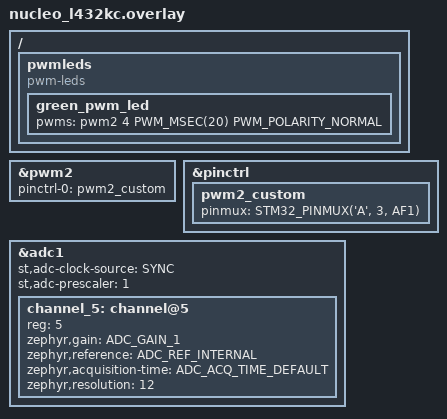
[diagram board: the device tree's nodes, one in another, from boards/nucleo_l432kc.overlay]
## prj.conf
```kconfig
CONFIG_PWM=y
CONFIG_ADC=y
CONFIG_GPIO=y
```

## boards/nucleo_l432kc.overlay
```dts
/{
    pwmleds: pwmleds {
        compatible = "pwm-leds";
        status = "okay";
        green_pwm_led: green_pwm_led {
            pwms = <&pwm2 4 PWM_MSEC(20) PWM_POLARITY_NORMAL>; // &pwm2 links to TIM2_CH4 and PA3
        };
    };
};

&pwm2 {
    status = "okay";
    pinctrl-0 = <&pwm2_custom>;
};

&pinctrl {
    pwm2_custom: pwm2_custom {
        pinmux = <STM32_PINMUX('A', 3, AF1)>; // Alternative function AF1 for this pin
    };
};

/* Enable and configure the ADC */
&adc1 {
    status = "okay";
    st,adc-clock-source = "SYNC";
    st,adc-prescaler = <1>;
    #address-cells = <1>;
    #size-cells = <0>;
    
    channel_5: channel@5 {  // Channel 5 linked to pin PA0
        reg = <5>;
        zephyr,gain = "ADC_GAIN_1";
        zephyr,reference = "ADC_REF_INTERNAL";
        zephyr,acquisition-time = <ADC_ACQ_TIME_DEFAULT>;
        zephyr,resolution = <12>;
    };
};
```

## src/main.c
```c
/*
Program 10: Control a motor or light bulb using the PWM output
Description: 
Course: 1064
Author: Daniel Mui
Date: 16/2/2026
 */

 //import tariffs
#include <zephyr/device.h>
#include <zephyr/drivers/pwm.h>
#include <zephyr/drivers/adc.h>

// Create our PWM device
static const struct pwm_dt_spec pwm_led0 = PWM_DT_SPEC_GET(DT_NODELABEL(green_pwm_led));

// Create our ADC device
static const struct device *const adc_dev1 = DEVICE_DT_GET(DT_NODELABEL(adc1));

// Create variable adc_ch1_cfg with the configuration parameters from Overlay
static const struct adc_channel_cfg adc_ch1_cfg = ADC_CHANNEL_CFG_DT(
    DT_CHILD(DT_NODELABEL(adc1), channel_5)
);

int main(void)
{
    uint32_t period = 1000000; 
    uint32_t pulse_width = 0;
    int16_t sample_buffer[1];
    struct adc_sequence sequence = {
        .buffer = sample_buffer,
        .buffer_size = sizeof(sample_buffer),
        .channels = BIT(5),
        .resolution = 12,
    };

    adc_channel_setup(adc_dev1, &adc_ch1_cfg);

    while (1) {
        //Read
        int err = adc_read(adc_dev, &sequence);

        int32_t adc_value = sample_buffer;
        pulse_width = (adc_value * period) / 4095;

        //Write
        pwm_set_dt(&motor, period, pulse_width);

        k_sleep(K_MSEC(50));
    }
    return 0; //we write good code, we return 0
}
```
